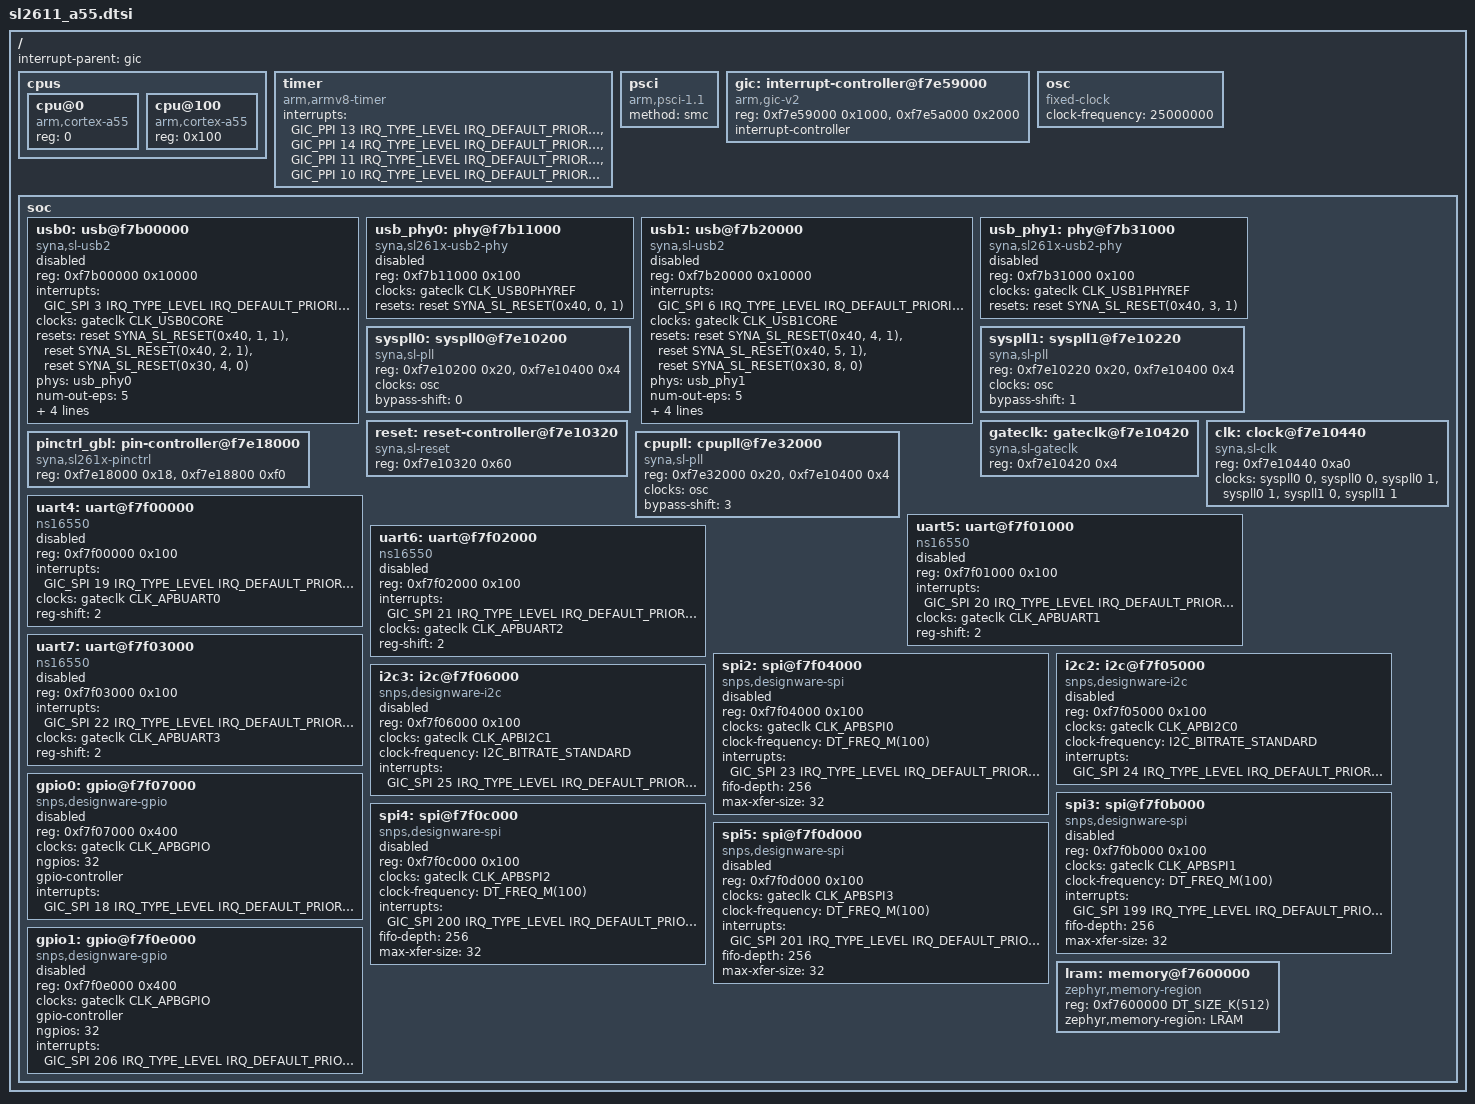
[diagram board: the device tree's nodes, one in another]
/*
 * Copyright (c) 2026 Synaptics Incorporated
 * Author: Jisheng Zhang <jszhang@kernel.org>
 *
 * SPDX-License-Identifier: Apache-2.0
 */

#include <mem.h>
#include <freq.h>
#include <arm64/armv8-a.dtsi>
#include <zephyr/dt-bindings/clock/syna_sl261x_a55_clock.h>
#include <zephyr/dt-bindings/gpio/gpio.h>
#include <zephyr/dt-bindings/i2c/i2c.h>
#include <zephyr/dt-bindings/interrupt-controller/arm-gic.h>
#include <zephyr/dt-bindings/reset/syna_sl_reset.h>

/ {
	#address-cells = <1>;
	#size-cells = <1>;
	interrupt-parent = <&gic>;

	cpus {
		#address-cells = <1>;
		#size-cells = <0>;

		cpu@0 {
			device_type = "cpu";
			compatible = "arm,cortex-a55";
			reg = <0>;
		};

		cpu@100 {
			device_type = "cpu";
			compatible = "arm,cortex-a55";
			reg = <0x100>;
		};
	};

	timer {
		compatible = "arm,armv8-timer";
		interrupts = <GIC_PPI 13 IRQ_TYPE_LEVEL IRQ_DEFAULT_PRIORITY>,
			     <GIC_PPI 14 IRQ_TYPE_LEVEL IRQ_DEFAULT_PRIORITY>,
			     <GIC_PPI 11 IRQ_TYPE_LEVEL IRQ_DEFAULT_PRIORITY>,
			     <GIC_PPI 10 IRQ_TYPE_LEVEL IRQ_DEFAULT_PRIORITY>;
	};

	psci: psci {
		compatible = "arm,psci-1.1";
		method = "smc";
	};

	gic: interrupt-controller@f7e59000 {
		compatible = "arm,gic-v2", "arm,gic";
		reg = <0xf7e59000 0x1000>,
		      <0xf7e5a000 0x2000>;
		interrupt-controller;
		#interrupt-cells = <4>;
	};

	osc: osc {
		compatible = "fixed-clock";
		#clock-cells = <0>;
		clock-frequency = <25000000>;
	};

	soc {
		#address-cells = <1>;
		#size-cells = <1>;
		ranges;

		usb0: usb@f7b00000 {
			compatible = "syna,sl-usb2", "snps,dwc2";
			reg = <0xf7b00000 0x10000>;
			interrupts = <GIC_SPI 3 IRQ_TYPE_LEVEL IRQ_DEFAULT_PRIORITY>;
			clocks = <&gateclk CLK_USB0CORE>;
			resets = <&reset SYNA_SL_RESET(0x40, 1, 1)>, <&reset SYNA_SL_RESET(0x40, 2, 1)>, <&reset SYNA_SL_RESET(0x30, 4, 0)>;
			phys = <&usb_phy0>;
			num-out-eps = <5>;
			num-in-eps = <5>;
			ghwcfg1 = <0x00000000>;
			ghwcfg2 = <0x238dd052>;
			ghwcfg4 = <0xd210ba20>;
			status = "disabled";
		};

		usb_phy0: phy@f7b11000 {
			compatible = "syna,sl261x-usb2-phy";
			reg = <0xf7b11000 0x100>;
			clocks = <&gateclk CLK_USB0PHYREF>;
			#phy-cells = <0>;
			resets = <&reset SYNA_SL_RESET(0x40, 0, 1)>;
			status = "disabled";
		};

		usb1: usb@f7b20000 {
			compatible = "syna,sl-usb2", "snps,dwc2";
			reg = <0xf7b20000 0x10000>;
			interrupts = <GIC_SPI 6 IRQ_TYPE_LEVEL IRQ_DEFAULT_PRIORITY>;
			clocks = <&gateclk CLK_USB1CORE>;
			resets = <&reset SYNA_SL_RESET(0x40, 4, 1)>, <&reset SYNA_SL_RESET(0x40, 5, 1)>, <&reset SYNA_SL_RESET(0x30, 8, 0)>;
			phys = <&usb_phy1>;
			num-out-eps = <5>;
			num-in-eps = <5>;
			ghwcfg1 = <0x00000000>;
			ghwcfg2 = <0x238dd052>;
			ghwcfg4 = <0xd210ba20>;
			status = "disabled";
		};

		usb_phy1: phy@f7b31000 {
			compatible = "syna,sl261x-usb2-phy";
			reg = <0xf7b31000 0x100>;
			clocks = <&gateclk CLK_USB1PHYREF>;
			#phy-cells = <0>;
			resets = <&reset SYNA_SL_RESET(0x40, 3, 1)>;
			status = "disabled";
		};

		syspll0: syspll0@f7e10200 {
			compatible = "syna,sl-pll";
			reg = <0xf7e10200 0x20>, <0xf7e10400 0x4>;
			#clock-cells = <1>;
			clocks = <&osc>;
			bypass-shift = <0>;
		};

		syspll1: syspll1@f7e10220 {
			compatible = "syna,sl-pll";
			reg = <0xf7e10220 0x20>, <0xf7e10400 0x4>;
			#clock-cells = <1>;
			clocks = <&osc>;
			bypass-shift = <1>;
		};

		reset: reset-controller@f7e10320 {
			compatible = "syna,sl-reset";
			reg = <0xf7e10320 0x60>;
			#reset-cells = <1>;
		};

		gateclk: gateclk@f7e10420 {
			compatible = "syna,sl-gateclk";
			reg = <0xf7e10420 0x4>;
			#clock-cells = <1>;
		};

		clk: clock@f7e10440 {
			compatible = "syna,sl-clk";
			reg = <0xf7e10440 0xa0>;
			clocks = <&syspll0 0>, <&syspll0 0>, <&syspll0 1>, <&syspll0 1>, <&syspll1 0>, <&syspll1 1>;
			#clock-cells = <1>;
		};

		pinctrl_gbl: pin-controller@f7e18000 {
			compatible = "syna,sl261x-pinctrl";
			reg = <0xf7e18000 0x18>, <0xf7e18800 0xf0>;
			reg-names = "pinmux", "pincfg";
		};

		cpupll: cpupll@f7e32000 {
			compatible = "syna,sl-pll";
			reg = <0xf7e32000 0x20>, <0xf7e10400 0x4>;
			#clock-cells = <1>;
			clocks = <&osc>;
			bypass-shift = <3>;
		};

		uart4: uart@f7f00000 {
			compatible = "ns16550";
			reg = <0xf7f00000 0x100>;
			interrupts = <GIC_SPI 19 IRQ_TYPE_LEVEL IRQ_DEFAULT_PRIORITY>;
			clocks = <&gateclk CLK_APBUART0>;
			reg-shift = <2>;
			status = "disabled";
		};

		uart5: uart@f7f01000 {
			compatible = "ns16550";
			reg = <0xf7f01000 0x100>;
			interrupts = <GIC_SPI 20 IRQ_TYPE_LEVEL IRQ_DEFAULT_PRIORITY>;
			clocks = <&gateclk CLK_APBUART1>;
			reg-shift = <2>;
			status = "disabled";
		};

		uart6: uart@f7f02000 {
			compatible = "ns16550";
			reg = <0xf7f02000 0x100>;
			interrupts = <GIC_SPI 21 IRQ_TYPE_LEVEL IRQ_DEFAULT_PRIORITY>;
			clocks = <&gateclk CLK_APBUART2>;
			reg-shift = <2>;
			status = "disabled";
		};

		uart7: uart@f7f03000 {
			compatible = "ns16550";
			reg = <0xf7f03000 0x100>;
			interrupts = <GIC_SPI 22 IRQ_TYPE_LEVEL IRQ_DEFAULT_PRIORITY>;
			clocks = <&gateclk CLK_APBUART3>;
			reg-shift = <2>;
			status = "disabled";
		};

		spi2: spi@f7f04000 {
			compatible = "snps,designware-spi";
			reg = <0xf7f04000 0x100>;
			#address-cells = <1>;
			#size-cells = <0>;
			clocks = <&gateclk CLK_APBSPI0>;
			clock-frequency = <DT_FREQ_M(100)>;
			interrupts = <GIC_SPI 23 IRQ_TYPE_LEVEL IRQ_DEFAULT_PRIORITY>;
			fifo-depth = <256>;
			max-xfer-size = <32>;
			status = "disabled";
		};

		i2c2: i2c@f7f05000 {
			compatible = "snps,designware-i2c";
			#address-cells = <1>;
			#size-cells = <0>;
			reg = <0xf7f05000 0x100>;
			clocks = <&gateclk CLK_APBI2C0>;
			clock-frequency = <I2C_BITRATE_STANDARD>;
			interrupts = <GIC_SPI 24 IRQ_TYPE_LEVEL IRQ_DEFAULT_PRIORITY>;
			status = "disabled";
		};

		i2c3: i2c@f7f06000 {
			compatible = "snps,designware-i2c";
			#address-cells = <1>;
			#size-cells = <0>;
			reg = <0xf7f06000 0x100>;
			clocks = <&gateclk CLK_APBI2C1>;
			clock-frequency = <I2C_BITRATE_STANDARD>;
			interrupts = <GIC_SPI 25 IRQ_TYPE_LEVEL IRQ_DEFAULT_PRIORITY>;
			status = "disabled";
		};

		gpio0: gpio@f7f07000 {
			compatible = "snps,designware-gpio";
			reg = <0xf7f07000 0x400>;
			#address-cells = <1>;
			#size-cells = <0>;
			clocks = <&gateclk CLK_APBGPIO>;
			ngpios = <32>;
			gpio-controller;
			#gpio-cells = <2>;
			interrupts = <GIC_SPI 18 IRQ_TYPE_LEVEL IRQ_DEFAULT_PRIORITY>;
			status = "disabled";
		};

		spi3: spi@f7f0b000 {
			compatible = "snps,designware-spi";
			reg = <0xf7f0b000 0x100>;
			#address-cells = <1>;
			#size-cells = <0>;
			clocks = <&gateclk CLK_APBSPI1>;
			clock-frequency = <DT_FREQ_M(100)>;
			interrupts = <GIC_SPI 199 IRQ_TYPE_LEVEL IRQ_DEFAULT_PRIORITY>;
			fifo-depth = <256>;
			max-xfer-size = <32>;
			status = "disabled";
		};

		spi4: spi@f7f0c000 {
			compatible = "snps,designware-spi";
			reg = <0xf7f0c000 0x100>;
			#address-cells = <1>;
			#size-cells = <0>;
			clocks = <&gateclk CLK_APBSPI2>;
			clock-frequency = <DT_FREQ_M(100)>;
			interrupts = <GIC_SPI 200 IRQ_TYPE_LEVEL IRQ_DEFAULT_PRIORITY>;
			fifo-depth = <256>;
			max-xfer-size = <32>;
			status = "disabled";
		};

		spi5: spi@f7f0d000 {
			compatible = "snps,designware-spi";
			reg = <0xf7f0d000 0x100>;
			#address-cells = <1>;
			#size-cells = <0>;
			clocks = <&gateclk CLK_APBSPI3>;
			clock-frequency = <DT_FREQ_M(100)>;
			interrupts = <GIC_SPI 201 IRQ_TYPE_LEVEL IRQ_DEFAULT_PRIORITY>;
			fifo-depth = <256>;
			max-xfer-size = <32>;
			status = "disabled";
		};

		gpio1: gpio@f7f0e000 {
			compatible = "snps,designware-gpio";
			reg = <0xf7f0e000 0x400>;
			#address-cells = <1>;
			#size-cells = <0>;
			clocks = <&gateclk CLK_APBGPIO>;
			gpio-controller;
			#gpio-cells = <2>;
			ngpios = <32>;
			interrupts = <GIC_SPI 206 IRQ_TYPE_LEVEL IRQ_DEFAULT_PRIORITY>;
			status = "disabled";
		};

		lram: memory@f7600000 {
			compatible = "zephyr,memory-region", "mmio-sram";
			reg = <0xf7600000 DT_SIZE_K(512)>;
			zephyr,memory-region = "LRAM";
		};
	};
};
